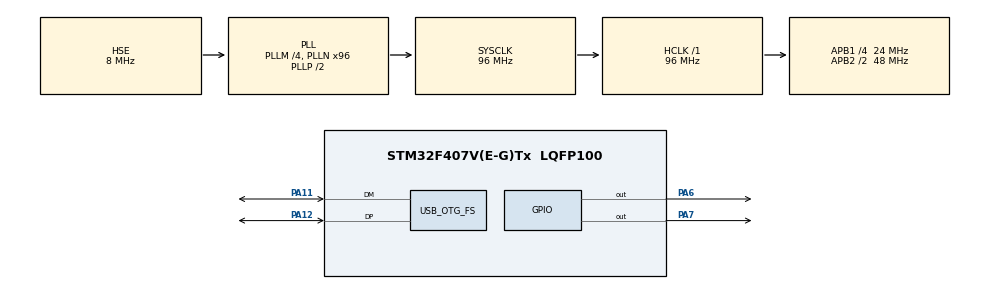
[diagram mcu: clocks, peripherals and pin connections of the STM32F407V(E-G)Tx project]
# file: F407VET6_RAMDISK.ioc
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Mcu.Family=STM32F4
Mcu.Name=STM32F407V(E-G)Tx
Mcu.Package=LQFP100
NVIC.OTG_FS_IRQn=true\:0\:0\:false\:false\:true\:false\:true
NVIC.PriorityGroup=NVIC_PRIORITYGROUP_4
PA11.Mode=Device_Only
PA11.Signal=USB_OTG_FS_DM
PA12.Mode=Device_Only
PA12.Signal=USB_OTG_FS_DP
PA13.Mode=Serial_Wire
PA13.Signal=SYS_JTMS-SWDIO
PA14.Mode=Serial_Wire
PA14.Signal=SYS_JTCK-SWCLK
PA6.Signal=GPIO_Output
PA7.Signal=GPIO_Output
PH0-OSC_IN.Mode=HSE-External-Oscillator
PH0-OSC_IN.Signal=RCC_OSC_IN
PH1-OSC_OUT.Mode=HSE-External-Oscillator
PH1-OSC_OUT.Signal=RCC_OSC_OUT
ProjectManager.HeapSize=0x1000
ProjectManager.StackSize=0x0800
ProjectManager.TargetToolchain=SW4STM32
RCC.48MHZClocksFreq_Value=48000000
RCC.AHBFreq_Value=96000000
RCC.APB1CLKDivider=RCC_HCLK_DIV4
RCC.APB1Freq_Value=24000000
RCC.APB1TimFreq_Value=48000000
RCC.APB2CLKDivider=RCC_HCLK_DIV2
RCC.APB2Freq_Value=48000000
RCC.APB2TimFreq_Value=96000000
RCC.CortexFreq_Value=96000000
RCC.HCLKFreq_Value=96000000
RCC.HSE_VALUE=8000000
RCC.HSI_VALUE=16000000
RCC.LSE_VALUE=32768
RCC.PLLM=4
RCC.PLLN=96
RCC.SYSCLKFreq_VALUE=96000000
RCC.SYSCLKSource=RCC_SYSCLKSOURCE_PLLCLK
RCC.VCOOutputFreq_Value=192000000
USB_DEVICE.CLASS_NAME_FS=MSC
USB_DEVICE.VirtualMode-MSC_FS=Msc
USB_DEVICE.VirtualModeFS=Msc_FS
USB_OTG_FS.VirtualMode=Device_Only
VP_USB_DEVICE_VS_USB_DEVICE_MSC_FS.Mode=MSC_FS
board=custom

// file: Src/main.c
/* USER CODE BEGIN Header */
/**
  ******************************************************************************
  * @file           : main.c
  * @brief          : Main program body
  ******************************************************************************
  * @attention
  *
  * <h2><center>&copy; Copyright (c) 2019 STMicroelectronics.
  * All rights reserved.</center></h2>
  *
  * This software component is licensed by ST under Ultimate Liberty license
  * SLA0044, the "License"; You may not use this file except in compliance with
  * the License. You may obtain a copy of the License at:
  *                             www.st.com/SLA0044
  *
  ******************************************************************************
  */
/* USER CODE END Header */

#include "main.h"
#include "usb_device.h"

/* USER CODE BEGIN Includes */
/* RAM Disk initializer */
int8_t STORAGE_FileSystem_Init (void);
/* USER CODE END Includes */

void SystemClock_Config(void);
static void MX_GPIO_Init(void);

int main(void)
{
  /* USER CODE BEGIN 1 */
	STORAGE_FileSystem_Init();

  /* USER CODE END 1 */

  /* MCU Configuration--------------------------------------------------------*/

  /* Reset of all peripherals, Initializes the Flash interface and the Systick. */
  HAL_Init();

  /* Configure the system clock */
  SystemClock_Config();

  /* Initialize all configured peripherals */
  MX_GPIO_Init();
  MX_USB_DEVICE_Init();
  /* USER CODE BEGIN 2 */
  HAL_GPIO_WritePin(GPIOA, GPIO_PIN_7, GPIO_PIN_SET);
  HAL_GPIO_WritePin(GPIOA, GPIO_PIN_6, GPIO_PIN_SET);
  /* USER CODE END 2 */

  /* Infinite loop */
  while (1)
  {

  }
}

void SystemClock_Config(void)
{
  RCC_OscInitTypeDef RCC_OscInitStruct = {0};
  RCC_ClkInitTypeDef RCC_ClkInitStruct = {0};

  /** Configure the main internal regulator output voltage
  */
  __HAL_RCC_PWR_CLK_ENABLE();
  __HAL_PWR_VOLTAGESCALING_CONFIG(PWR_REGULATOR_VOLTAGE_SCALE1);
  /** Initializes the CPU, AHB and APB busses clocks
  */
  RCC_OscInitStruct.OscillatorType = RCC_OSCILLATORTYPE_HSE;
  RCC_OscInitStruct.HSEState = RCC_HSE_ON;
  RCC_OscInitStruct.PLL.PLLState = RCC_PLL_ON;
  RCC_OscInitStruct.PLL.PLLSource = RCC_PLLSOURCE_HSE;
  RCC_OscInitStruct.PLL.PLLM = 4;
  RCC_OscInitStruct.PLL.PLLN = 96;
  RCC_OscInitStruct.PLL.PLLP = RCC_PLLP_DIV2;
  RCC_OscInitStruct.PLL.PLLQ = 4;
  if (HAL_RCC_OscConfig(&RCC_OscInitStruct) != HAL_OK)
  {
    Error_Handler();
  }
  /** Initializes the CPU, AHB and APB busses clocks
  */
  RCC_ClkInitStruct.ClockType = RCC_CLOCKTYPE_HCLK|RCC_CLOCKTYPE_SYSCLK
                              |RCC_CLOCKTYPE_PCLK1|RCC_CLOCKTYPE_PCLK2;
  RCC_ClkInitStruct.SYSCLKSource = RCC_SYSCLKSOURCE_PLLCLK;
  RCC_ClkInitStruct.AHBCLKDivider = RCC_SYSCLK_DIV1;
  RCC_ClkInitStruct.APB1CLKDivider = RCC_HCLK_DIV4;
  RCC_ClkInitStruct.APB2CLKDivider = RCC_HCLK_DIV2;

  if (HAL_RCC_ClockConfig(&RCC_ClkInitStruct, FLASH_LATENCY_3) != HAL_OK)
  {
    Error_Handler();
  }
}

static void MX_GPIO_Init(void)
{
  GPIO_InitTypeDef GPIO_InitStruct = {0};

  /* GPIO Ports Clock Enable */
  __HAL_RCC_GPIOH_CLK_ENABLE();
  __HAL_RCC_GPIOA_CLK_ENABLE();

  /*Configure GPIO pin Output Level */
  HAL_GPIO_WritePin(GPIOA, GPIO_PIN_6|GPIO_PIN_7|GPIO_PIN_12 , GPIO_PIN_RESET);

  /*Configure GPIO pins : PA6 PA7 */
  GPIO_InitStruct.Pin = GPIO_PIN_6|GPIO_PIN_7|GPIO_PIN_12;
  GPIO_InitStruct.Mode = GPIO_MODE_OUTPUT_PP;
  GPIO_InitStruct.Pull = GPIO_NOPULL;
  GPIO_InitStruct.Speed = GPIO_SPEED_FREQ_LOW;
  HAL_GPIO_Init(GPIOA, &GPIO_InitStruct);
  //for (volatile uint32_t i = 0; i<5000000; i++);
  HAL_Delay(500);
}

void Error_Handler(void)
{
}

/************************ (C) COPYRIGHT STMicroelectronics *****END OF FILE****/
